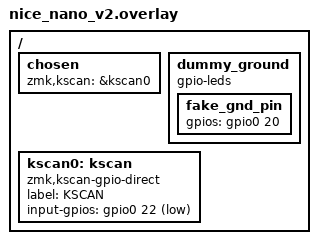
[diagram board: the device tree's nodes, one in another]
/ {
    chosen {
        zmk,kscan = &kscan0;
    };

    // Force P0.24 to act as a Ground (Low) pin
    dummy_ground {
        compatible = "gpio-leds";
        fake_gnd_pin {
            gpios = <&gpio0 24 GPIO_ACTIVE_HIGH>; 
            // Leaving this unbound without a 'label' forces the pin state 
            // to initial default low, acting as a constant GND drain.
        };
    };

    // Force P0.20 to act as a Ground (Low) pin
    dummy_ground {
        compatible = "gpio-leds";
        fake_gnd_pin {
            gpios = <&gpio0 20 GPIO_ACTIVE_HIGH>; 
            // Leaving this unbound without a 'label' forces the pin state 
            // to initial default low, acting as a constant GND drain.
        };
    };

    kscan0: kscan {
        compatible = "zmk,kscan-gpio-direct";
        label = "KSCAN";
        input-gpios
            = <&gpio0 22 (GPIO_ACTIVE_LOW | GPIO_PULL_UP)>; // Pin 4 (P0.22)
    };
};
